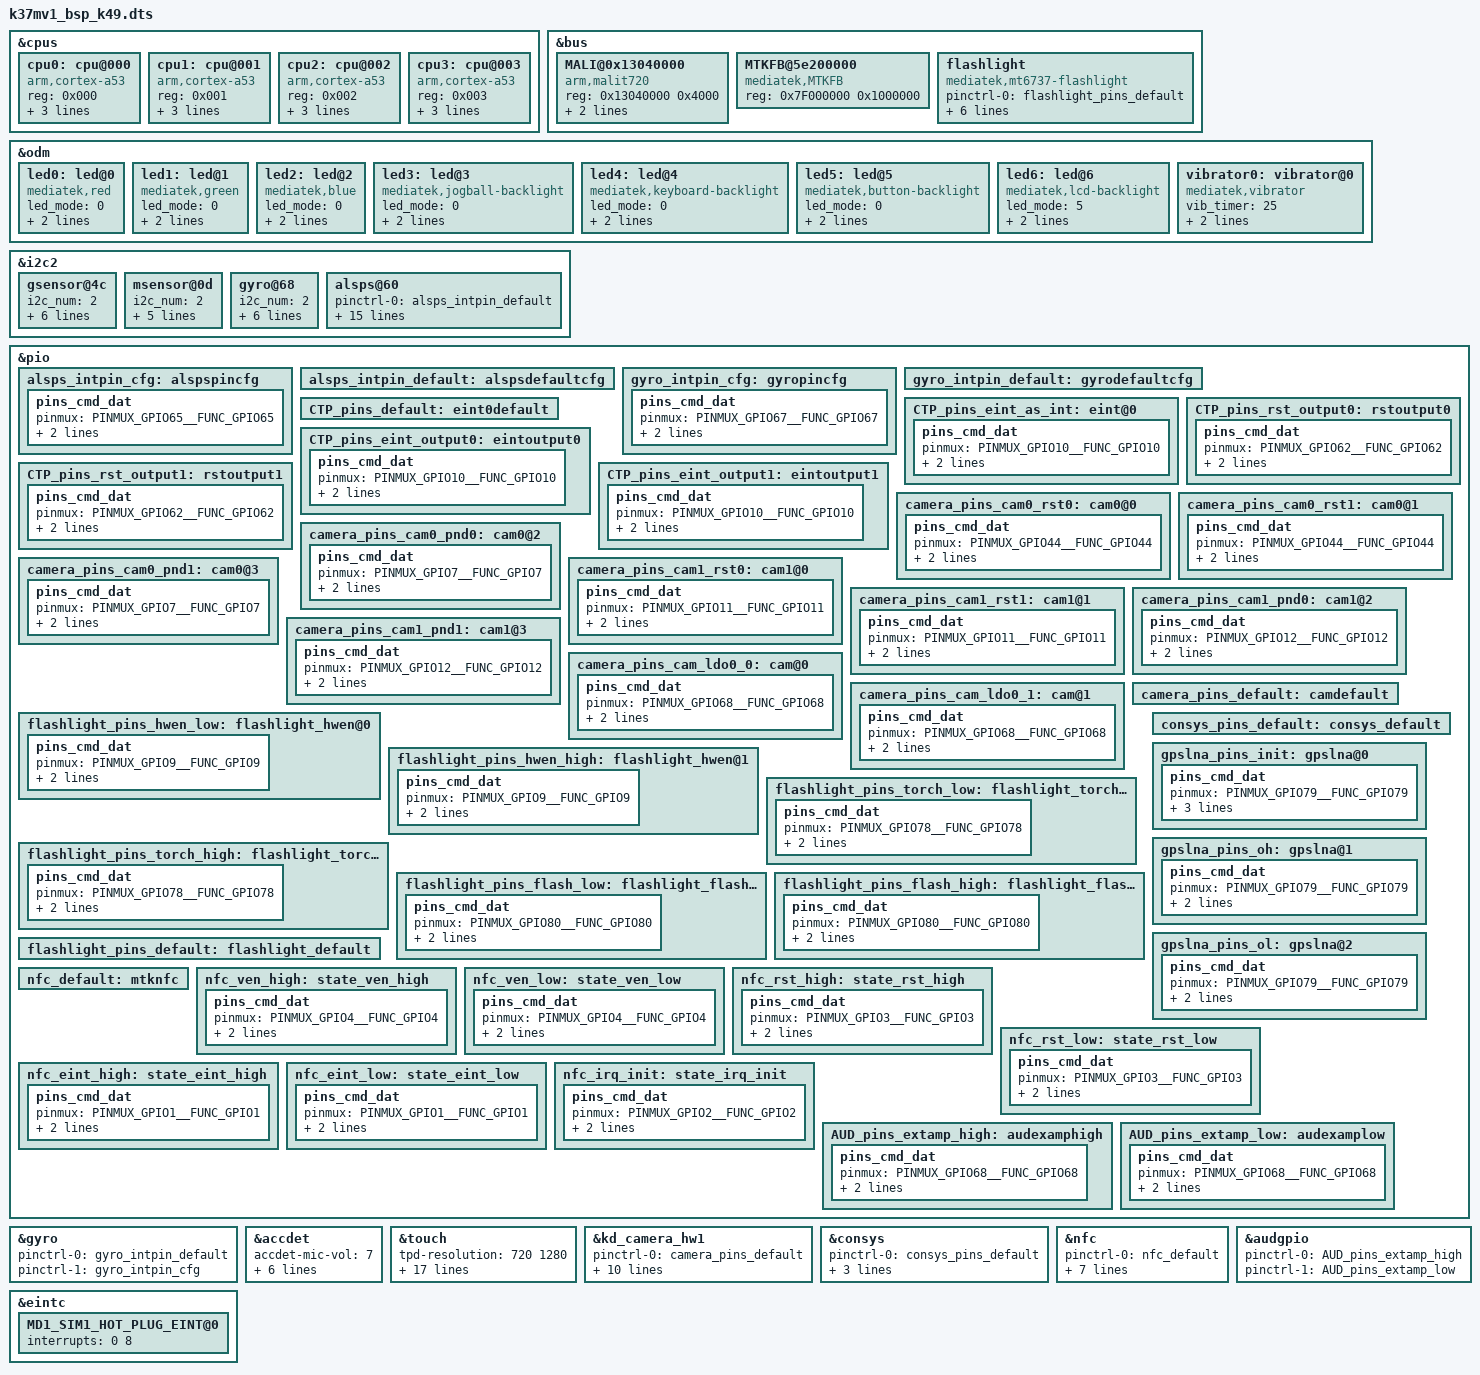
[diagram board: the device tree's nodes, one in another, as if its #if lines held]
#include <generated/autoconf.h>
/dts-v1/;

#ifdef CONFIG_MTK_DTBO_FEATURE
/plugin/;
#include "mt6735m-pinfunc.h"
#include <dt-bindings/mmc/mt6735-msdc.h>
#else
#include "mt6735m.dts"
#endif
#include <dt-bindings/lcm/otm9608_qhd_dsi_cmd.dtsi>

&cpus {
	#address-cells = <1>;
	#size-cells = <0>;
	/*enable-method = "mediatek,mt6735-smp"; */

	cpu0: cpu@000 {
		device_type = "cpu";
		compatible = "arm,cortex-a53";
		reg = <0x000>;
		enable-method = "spin-table";
		cpu-release-addr = <0x0 0x40000200>;
		clock-frequency = <1100000000>;
	};

	cpu1: cpu@001 {
		device_type = "cpu";
		compatible = "arm,cortex-a53";
		reg = <0x001>;
		enable-method = "spin-table";
		cpu-release-addr = <0x0 0x40000200>;
		clock-frequency = <1100000000>;
	};

	cpu2: cpu@002 {
		device_type = "cpu";
		compatible = "arm,cortex-a53";
		reg = <0x002>;
		enable-method = "spin-table";
		cpu-release-addr = <0x0 0x40000200>;
		clock-frequency = <1100000000>;
	};

	cpu3: cpu@003 {
		device_type = "cpu";
		compatible = "arm,cortex-a53";
		reg = <0x003>;
		enable-method = "spin-table";
		cpu-release-addr = <0x0 0x40000200>;
		clock-frequency = <1100000000>;
	};
};

&bus {
	MALI@0x13040000 {
		compatible = "arm,malit720", "arm,mali-t72x", "arm,malit7xx", "arm,mali-midgard";
		reg = <0x13040000 0x4000>;
		interrupts = <0 212 0x8>, <0 211 0x8>, <0 210 0x8>;
		interrupt-names = "JOB", "MMU", "GPU";
		clock-frequency = <550000000>;
	};

	MTKFB@5e200000 {
		compatible = "mediatek,MTKFB";
		reg = <0x7F000000 0x1000000>;
	};
};

&odm {
	led0:led@0 {
		compatible = "mediatek,red";
		led_mode = <0>;
		data = <1>;
		pwm_config = <0 0 0 0 0>;
	};
	led1:led@1 {
		compatible = "mediatek,green";
		led_mode = <0>;
		data = <1>;
		pwm_config = <0 0 0 0 0>;
	};
	led2:led@2 {
		compatible = "mediatek,blue";
		led_mode = <0>;
		data = <1>;
		pwm_config = <0 0 0 0 0>;
	};
	led3:led@3 {
		compatible = "mediatek,jogball-backlight";
		led_mode = <0>;
		data = <1>;
		pwm_config = <0 0 0 0 0>;
	};
	led4:led@4 {
		compatible = "mediatek,keyboard-backlight";
		led_mode = <0>;
		data = <1>;
		pwm_config = <0 0 0 0 0>;
	};
	led5:led@5 {
		compatible = "mediatek,button-backlight";
		led_mode = <0>;
		data = <1>;
		pwm_config = <0 0 0 0 0>;
	};
	led6:led@6 {
		compatible = "mediatek,lcd-backlight";
		led_mode = <5>;
		data = <1>;
		pwm_config = <0 0 0 0 0>;
	};
	vibrator0:vibrator@0 {
		compatible = "mediatek,vibrator";
		vib_timer = <25>;
		vib_limit = <9>;
		vib_vol= <5>;
	};
};

&i2c2 {
/* start sensor */
	gsensor@4c {
		i2c_num = <2>;
		i2c_addr = <0x4c 0 0 0>;
		direction = <0>;
		power_id = <0xffff>;
		power_vol = <0>;
		firlen = <0>;
		is_batch_supported = <0>;
	};

	msensor@0d {
		i2c_num = <2>;
		i2c_addr = <0x0D 0 0 0>;
		direction = <1>;
		power_id = <0xffff>;
		power_vol = <0>;
		is_batch_supported = <0>;
	};

	gyro@68 {
		i2c_num = <2>;
		i2c_addr = <0x68 0 0 0>;
		direction = <3>;
		power_id = <0xffff>;
		power_vol = <0>;
		firlen = <0>;
		is_batch_supported = <0>;
	};

	alsps@60 {
		pinctrl-names = "pin_default", "pin_cfg";
		pinctrl-0 = <&alsps_intpin_default>;
		pinctrl-1 = <&alsps_intpin_cfg>;
		status = "okay";
		/* customization */
		i2c_num = <2>;
		i2c_addr = <0x60 0 0 0>;
		polling_mode_ps = <0>;
		polling_mode_als = <1>;
		power_id = <0xffff>;
		power_vol = <0>;
		als_level = <0 328 861 1377 3125 7721 7767 12621 23062 28430 33274 47116 57694 57694 65535>;
		als_value = <0 133 304 502 1004 2005 3058 5005 8008 10010 12000 16000 20000 20000 20000 20000>;
		ps_threshold_high =  <34>;
		ps_threshold_low =  <28>;
		is_batch_supported_ps = <0>;
		is_batch_supported_als = <0>;
	};
};

/* sensor gpio standization */
&pio {
	alsps_intpin_cfg: alspspincfg {

		pins_cmd_dat {
			pinmux = <PINMUX_GPIO65__FUNC_GPIO65>;
			slew-rate = <0>;
			bias-pull-up = <00>;
		};
	};

	alsps_intpin_default: alspsdefaultcfg {

	};

	gyro_intpin_cfg: gyropincfg {

		pins_cmd_dat {
			pinmux = <PINMUX_GPIO67__FUNC_GPIO67>;
			slew-rate = <0>;
			bias-pull-down = <00>;
		};
	};

	gyro_intpin_default: gyrodefaultcfg {

	};
};

&gyro {
	pinctrl-names = "pin_default", "pin_cfg";
	pinctrl-0 = <&gyro_intpin_default>;
	pinctrl-1 = <&gyro_intpin_cfg>;
	status = "okay";

};
/* sensor end */

&accdet {
		accdet-mic-vol = <7>;
		headset-mode-setting = <0x500 0x200 1 0x1F0 0x800 0x800 0x20>;
		accdet-plugout-debounce = <20>;
		/*1:ACC mode, 2:low cost without in bias, 6:low cost with in bias*/
		accdet-mic-mode = <6>;
		/*0--MD_MAX--UP_MAX--DW_MAX*/
		headset-three-key-threshold = <0 80 220 500>;
		/*0--MD_MAX--VOICE_MAX--UP_MAX--DW_MAX*/
		headset-four-key-threshold = <0 58 121 192 450>;
};
&touch {
	tpd-resolution = <720 1280>;
	use-tpd-button = <0>;
	tpd-key-num = <3>;
	tpd-key-local= <139 172 158 0>;
	tpd-key-dim-local = <90 883 100 40 230 883 100 40 370 883 100 40 0 0 0 0>;
	tpd-max-touch-num = <5>;
	tpd-filter-enable = <1>;
	tpd-filter-pixel-density = <124>;
	tpd-filter-custom-prameters = <0 0 0 0 0 0 0 0 0 0 0 0>;
	tpd-filter-custom-speed = <0 0 0>;
	pinctrl-names = "default", "state_eint_as_int", "state_eint_output0", "state_eint_output1",
		"state_rst_output0", "state_rst_output1";
	pinctrl-0 = <&CTP_pins_default>;
	pinctrl-1 = <&CTP_pins_eint_as_int>;
	pinctrl-2 = <&CTP_pins_eint_output0>;
	pinctrl-3 = <&CTP_pins_eint_output1>;
	pinctrl-4 = <&CTP_pins_rst_output0>;
	pinctrl-5 = <&CTP_pins_rst_output1>;
	status = "okay";
};
&pio {
	CTP_pins_default: eint0default {
	};
	CTP_pins_eint_as_int: eint@0 {
		pins_cmd_dat {
			pinmux = <PINMUX_GPIO10__FUNC_GPIO10>;
			slew-rate = <0>;
			bias-disable;
		};
	};
	CTP_pins_eint_output0: eintoutput0 {
		pins_cmd_dat {
			pinmux = <PINMUX_GPIO10__FUNC_GPIO10>;
			slew-rate = <1>;
			output-low;
		};
	};
	CTP_pins_eint_output1: eintoutput1 {
		pins_cmd_dat {
			pinmux = <PINMUX_GPIO10__FUNC_GPIO10>;
			slew-rate = <1>;
			output-high;
		};
	};
	CTP_pins_rst_output0: rstoutput0 {
		pins_cmd_dat {
			pinmux = <PINMUX_GPIO62__FUNC_GPIO62>;
			slew-rate = <1>;
			output-low;
		};
	};
	CTP_pins_rst_output1: rstoutput1 {
		pins_cmd_dat {
			pinmux = <PINMUX_GPIO62__FUNC_GPIO62>;
			slew-rate = <1>;
			output-high;
		};
	};
};
/* TOUCH end */
/* CAMERA GPIO standardization */
&pio {
	camera_pins_cam0_rst0: cam0@0 {
		pins_cmd_dat {
			pinmux = <PINMUX_GPIO44__FUNC_GPIO44>;/*GPIO_CAMERA_CMRST_PIN*/
			slew-rate = <1>; /*direction 0:in, 1:out*/
			output-low;/*direction out used only. output_low or high*/
		};
	};
	camera_pins_cam0_rst1: cam0@1 {
		pins_cmd_dat {
			pinmux = <PINMUX_GPIO44__FUNC_GPIO44>;/*GPIO_CAMERA_CMRST_PIN*/
			slew-rate = <1>;
			output-high;
		};
	};
	camera_pins_cam0_pnd0: cam0@2 {
		pins_cmd_dat {
			pinmux = <PINMUX_GPIO7__FUNC_GPIO7>;/*GPIO_CAMERA_CMPDN_PIN*/
			slew-rate = <1>;
			output-low;
		};
	};
	camera_pins_cam0_pnd1: cam0@3 {
		pins_cmd_dat {
			pinmux = <PINMUX_GPIO7__FUNC_GPIO7>;/*GPIO_CAMERA_CMPDN_PIN*/
			slew-rate = <1>;
			output-high;
		};
	};
	camera_pins_cam1_rst0: cam1@0 {
		pins_cmd_dat {
			pinmux = <PINMUX_GPIO11__FUNC_GPIO11>;/*GPIO_CAMERA_CMRST1_PIN*/
			slew-rate = <1>; /*direction 0:in, 1:out*/
			output-low;/*direction out used only. output_low or high*/
		};
	};
	camera_pins_cam1_rst1: cam1@1 {
		pins_cmd_dat {
			pinmux = <PINMUX_GPIO11__FUNC_GPIO11>;/*GPIO_CAMERA_CMRST1_PIN*/
			slew-rate = <1>;
			output-high;
		};
	};
	camera_pins_cam1_pnd0: cam1@2 {
		pins_cmd_dat {
			pinmux = <PINMUX_GPIO12__FUNC_GPIO12>;/*GPIO_CAMERA_CMPDN1_PIN*/
			slew-rate = <1>;
			output-low;
		};
	};
	camera_pins_cam1_pnd1: cam1@3 {
		pins_cmd_dat {
			pinmux = <PINMUX_GPIO12__FUNC_GPIO12>;/*GPIO_CAMERA_CMPDN1_PIN*/
			slew-rate = <1>;
			output-high;
		};
	};
	camera_pins_cam_ldo0_0: cam@0 {
		pins_cmd_dat {
			pinmux = <PINMUX_GPIO68__FUNC_GPIO68>;/*GPIO_SPI_MOSI_PIN*/
			slew-rate = <1>;
			output-low;
		};
	};
	camera_pins_cam_ldo0_1: cam@1 {
		pins_cmd_dat {
			pinmux = <PINMUX_GPIO68__FUNC_GPIO68>;/*GPIO_SPI_MOSI_PIN*/
			slew-rate = <1>;
			output-high;
		};
	};
	camera_pins_default: camdefault {
	};

};

&kd_camera_hw1 {
	pinctrl-names = "default", "cam0_rst0", "cam0_rst1", "cam0_pnd0", "cam0_pnd1",
			"cam1_rst0", "cam1_rst1", "cam1_pnd0", "cam1_pnd1","cam_ldo0_0", "cam_ldo0_1";
	pinctrl-0 = <&camera_pins_default>;
	pinctrl-1 = <&camera_pins_cam0_rst0>;
	pinctrl-2 = <&camera_pins_cam0_rst1>;
	pinctrl-3 = <&camera_pins_cam0_pnd0>;
	pinctrl-4 = <&camera_pins_cam0_pnd1>;
	pinctrl-5 = <&camera_pins_cam1_rst0>;
	pinctrl-6 = <&camera_pins_cam1_rst1>;
	pinctrl-7 = <&camera_pins_cam1_pnd0>;
	pinctrl-8 = <&camera_pins_cam1_pnd1>;
	pinctrl-9 = <&camera_pins_cam_ldo0_0>;
	pinctrl-10 = <&camera_pins_cam_ldo0_1>;
	status = "okay";

};
/* CAMERA GPIO end */

/* forge (m5c): the camera/flash i2c device nodes are generated from
 * drivers/misc/mediatek/dws/mt6735/k37mv1_bsp_k49.dws into
 * k37mv1_bsp_k49/cust.dtsi at build time; the DWS was patched so the
 * generated nodes match the stock DTB (camera_main@10, camera_main_af@18,
 * camera_sub@3c on i2c0, strobe_main@63 on i2c1). Do NOT hand-add them here
 * or they register twice. */

/* forge (m5c): flash chip control pins. Stock DT node
 * "mediatek,mt6737-flashlight" owns hwen (GPIO9), torch (GPIO78) and
 * flash (GPIO80) pinctrl states; the legacy kd_flashlightlist driver binds
 * this node and selects the states by name. */
&pio {
	flashlight_pins_hwen_low: flashlight_hwen@0 {
		pins_cmd_dat {
			pinmux = <PINMUX_GPIO9__FUNC_GPIO9>;
			slew-rate = <1>;
			output-low;
		};
	};
	flashlight_pins_hwen_high: flashlight_hwen@1 {
		pins_cmd_dat {
			pinmux = <PINMUX_GPIO9__FUNC_GPIO9>;
			slew-rate = <1>;
			output-high;
		};
	};
	flashlight_pins_torch_low: flashlight_torch@0 {
		pins_cmd_dat {
			pinmux = <PINMUX_GPIO78__FUNC_GPIO78>;
			slew-rate = <1>;
			output-low;
		};
	};
	flashlight_pins_torch_high: flashlight_torch@1 {
		pins_cmd_dat {
			pinmux = <PINMUX_GPIO78__FUNC_GPIO78>;
			slew-rate = <1>;
			output-high;
		};
	};
	flashlight_pins_flash_low: flashlight_flash@0 {
		pins_cmd_dat {
			pinmux = <PINMUX_GPIO80__FUNC_GPIO80>;
			slew-rate = <1>;
			output-low;
		};
	};
	flashlight_pins_flash_high: flashlight_flash@1 {
		pins_cmd_dat {
			pinmux = <PINMUX_GPIO80__FUNC_GPIO80>;
			slew-rate = <1>;
			output-high;
		};
	};
	flashlight_pins_default: flashlight_default {
	};
};

&bus {
	flashlight {
		compatible = "mediatek,mt6737-flashlight";
		pinctrl-names = "default", "hwen_low", "hwen_high", "torch_low",
				"torch_high", "flash_low", "flash_high";
		pinctrl-0 = <&flashlight_pins_default>;
		pinctrl-1 = <&flashlight_pins_hwen_low>;
		pinctrl-2 = <&flashlight_pins_hwen_high>;
		pinctrl-3 = <&flashlight_pins_torch_low>;
		pinctrl-4 = <&flashlight_pins_torch_high>;
		pinctrl-5 = <&flashlight_pins_flash_low>;
		pinctrl-6 = <&flashlight_pins_flash_high>;
		status = "okay";
	};
};

/* CONSYS GPIO standardization */
&pio {
	consys_pins_default: consys_default {

	};

	gpslna_pins_init: gpslna@0 {

		pins_cmd_dat {
			pinmux = <PINMUX_GPIO79__FUNC_GPIO79>;
			slew-rate = <0>;
			bias-disable;
			output-low;
		};
	};

	gpslna_pins_oh: gpslna@1 {

		pins_cmd_dat {
			pinmux = <PINMUX_GPIO79__FUNC_GPIO79>;
			slew-rate = <1>;
			output-high;
		};
	};

	gpslna_pins_ol: gpslna@2 {

		pins_cmd_dat {
			pinmux = <PINMUX_GPIO79__FUNC_GPIO79>;
			slew-rate = <1>;
			output-low;
		};
	};

};

&consys {
	pinctrl-names = "default", "gps_lna_state_init", "gps_lna_state_oh", "gps_lna_state_ol";
	pinctrl-0 = <&consys_pins_default>;
	pinctrl-1 = <&gpslna_pins_init>;
	pinctrl-2 = <&gpslna_pins_oh>;
	pinctrl-3 = <&gpslna_pins_ol>;
	status = "okay";

};
/* CONSYS end */

/* NFC GPIO standardization */
&pio {
	nfc_default: mtknfc {

	};

	nfc_ven_high: state_ven_high {
		pins_cmd_dat {
			pinmux = <PINMUX_GPIO4__FUNC_GPIO4>;
			slew-rate = <1>;
			output-high;
		};
	};

	nfc_ven_low: state_ven_low {
		pins_cmd_dat {
			pinmux = <PINMUX_GPIO4__FUNC_GPIO4>;
			slew-rate = <1>;
			output-low;
		};
	};

	nfc_rst_high: state_rst_high {
		pins_cmd_dat {
			pinmux = <PINMUX_GPIO3__FUNC_GPIO3>;
			slew-rate = <1>;
			output-high;
		};
	};

	nfc_rst_low: state_rst_low {
		pins_cmd_dat {
			pinmux = <PINMUX_GPIO3__FUNC_GPIO3>;
			slew-rate = <1>;
			output-low;
		};
	};

	nfc_eint_high: state_eint_high {
		pins_cmd_dat {
			pinmux = <PINMUX_GPIO1__FUNC_GPIO1>;
			slew-rate = <1>;
			output-high;
		};
	};

	nfc_eint_low: state_eint_low {
		pins_cmd_dat {
			pinmux = <PINMUX_GPIO1__FUNC_GPIO1>;
			slew-rate = <1>;
			output-low;
		};
	};

	nfc_irq_init: state_irq_init {
		pins_cmd_dat {
			pinmux = <PINMUX_GPIO2__FUNC_GPIO2>;
			slew-rate = <0>;
			bias-pull-down = <00>;
		};
	};
};

&nfc {
	pinctrl-names = "mtknfc", "ven_high", "ven_low", "rst_high", "rst_low", "eint_high", "eint_low", "irq_init";
	pinctrl-0 = <&nfc_default>;
	pinctrl-1 = <&nfc_ven_high>;
	pinctrl-2 = <&nfc_ven_low>;
	pinctrl-3 = <&nfc_rst_high>;
	pinctrl-4 = <&nfc_rst_low>;
	pinctrl-5 = <&nfc_eint_high>;
	pinctrl-6 = <&nfc_eint_low>;
	pinctrl-7 = <&nfc_irq_init>;
	status = "okay";
};
/* NFC end */

/* AUDIO GPIO standardization (stock m5c DTB: extamp on GPIO68, pinmux 0x4400) */
&pio {
	AUD_pins_extamp_high: audexamphigh {
		pins_cmd_dat {
			pinmux = <PINMUX_GPIO68__FUNC_GPIO68>;
			slew-rate = <1>;
			output-high;
		};
	};
	AUD_pins_extamp_low: audexamplow {
		pins_cmd_dat {
			pinmux = <PINMUX_GPIO68__FUNC_GPIO68>;
			slew-rate = <1>;
			output-low;
		};
	};
};

&audgpio {
	pinctrl-names = "extamp-pullhigh", "extamp-pulllow";
	pinctrl-0 = <&AUD_pins_extamp_high>;
	pinctrl-1 = <&AUD_pins_extamp_low>;
	status = "okay";
};
/* AUDIO end */

#include <k37mv1_bsp_k49/cust.dtsi>
/*End of this file, DO NOT ADD ANYTHING HERE*/

/* Stock-DTB conformance overrides for the modem SIM hot-plug EINT nodes.
 * These MUST stay after the cust.dtsi include above: cust.dtsi is
 * regenerated by drvgen (scripts/drvgen/drvgen.mk) from
 * drivers/misc/mediatek/dws/mt6735/k37mv1_bsp_k49.dws on every build,
 * so the generated values cannot be edited durably. dtc merges nodes by
 * name and the later definition wins, so this block overrides drvgen.
 *
 * Stock 3.18 DTB (hq6737m_65_1mz_m0.dts / dtb_stock.dtb) ships:
 *   MD1_SIM1_HOT_PLUG_EINT@0: interrupts = <0 8> (IRQ_TYPE_LEVEL_LOW)
 *   (no MD1_SIM2_HOT_PLUG_EINT node at all)
 * drvgen cust.dtsi emits interrupts = <0 4> (LEVEL_HIGH) and an extra
 * SIM2 node. eccci1 port_rpc.c decodes polarity/sensitivity from cell 1
 * of "interrupts" and looks nodes up by name ignoring "status", so the
 * polarity must be corrected and the SIM2 node deleted to match stock. */
&eintc {
	MD1_SIM1_HOT_PLUG_EINT@0 {
		interrupts = <0 8>;
	};
};

/delete-node/ &{/bus/eintc@10005000/MD1_SIM2_HOT_PLUG_EINT@1};
